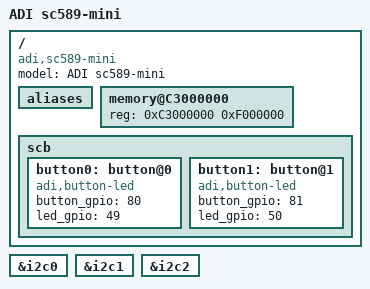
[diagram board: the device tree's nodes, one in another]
/*
 * Device tree for ADI sc589-mini board
 *
 * Copyright 2014 - 2018 Analog Devices Inc.
 *
 * Licensed under the GPL-2 or later.
 *
 */

/dts-v1/;

#include "sc58x.dtsi"

/ {
	model = "ADI sc589-mini";
	compatible = "adi,sc589-mini", "adi,sc58x";

	aliases {
	};

	memory@C3000000 {
		device_type = "memory";
		reg = <0xC3000000 0xF000000>;
	};

	scb {
		button0: button@0 {
			compatible = "adi,button-led";
			button_gpio = <80>;
			led_gpio = <49>;
		};
		button1: button@1 {
			compatible = "adi,button-led";
			button_gpio = <81>;
			led_gpio = <50>;
		};
	};
};

&i2c0 {
	status = "okay";
};

&i2c1 {
	status = "okay";
};

&i2c2 {
	status = "okay";
};
